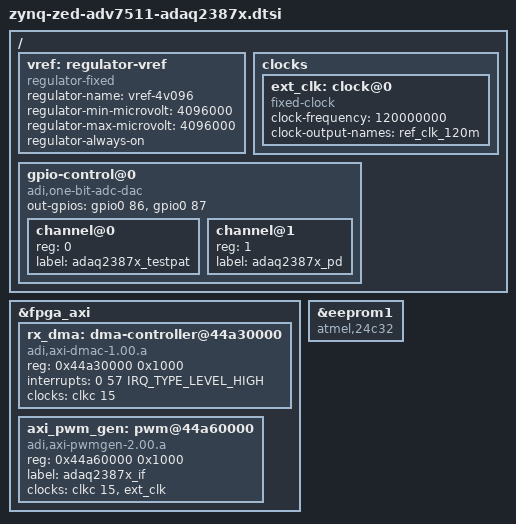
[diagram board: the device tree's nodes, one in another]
// SPDX-License-Identifier: GPL-2.0
/*
 * Shared carrier pieces for the ADAQ2387x modules on Zedboard.
 *
 * ext_clk must match the reference clock the HDL bitstream produces.
 *
 * Copyright (C) 2026 Analog Devices Inc.
 */

#include "zynq-zed.dtsi"
#include "zynq-zed-adv7511.dtsi"
#include <dt-bindings/gpio/gpio.h>
#include <dt-bindings/pwm/pwm.h>

/ {
	vref: regulator-vref {
		compatible = "regulator-fixed";
		regulator-name = "vref-4v096";
		regulator-min-microvolt = <4096000>;
		regulator-max-microvolt = <4096000>;
		regulator-always-on;
	};

	clocks {
		ext_clk: clock@0 {
			#clock-cells = <0>;
			compatible = "fixed-clock";
			clock-frequency = <120000000>;
			clock-output-names = "ref_clk_120m";
		};
	};

	gpio-control@0 {
		compatible = "adi,one-bit-adc-dac";
		#address-cells = <1>;
		#size-cells = <0>;
		out-gpios = <&gpio0 86 GPIO_ACTIVE_HIGH>,
			    <&gpio0 87 GPIO_ACTIVE_HIGH>;
		channel@0 {
			reg = <0>;
			label = "adaq2387x_testpat";
		};
		channel@1 {
			reg = <1>;
			label = "adaq2387x_pd";
		};
	};
};

&fpga_axi {
	rx_dma: dma-controller@44a30000 {
		compatible = "adi,axi-dmac-1.00.a";
		reg = <0x44a30000 0x1000>;
		#dma-cells = <1>;
		interrupts = <0 57 IRQ_TYPE_LEVEL_HIGH>;
		clocks = <&clkc 15>;
	};

	axi_pwm_gen: pwm@44a60000 {
		compatible = "adi,axi-pwmgen-2.00.a";
		reg = <0x44a60000 0x1000>;
		label = "adaq2387x_if";
		#pwm-cells = <2>;
		clocks = <&clkc 15>, <&ext_clk>;
		clock-names = "axi", "ext";
	};
};

/* The FMC FRU EEPROM on this card is a 24AA32A, not the carrier's default. */
&eeprom1 {
	compatible = "atmel,24c32";
};
